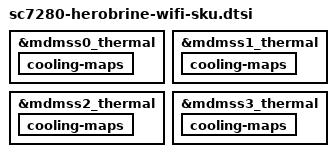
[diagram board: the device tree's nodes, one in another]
// SPDX-License-Identifier: BSD-3-Clause
/*
 * Google Herobrine dts fragment for WIFI SKUs
 *
 * Copyright (c) 2022 Qualcomm Innovation Center, Inc. All rights reserved.
 */

/* WIFI SKUs save 256M by not having modem/mba/rmtfs memory regions defined. */

&mdmss0_thermal {
	cooling-maps {
		/delete-node/ map0;
		/delete-node/ map1;
	};
};

&mdmss1_thermal {
	cooling-maps {
		/delete-node/ map0;
		/delete-node/ map1;
	};
};

&mdmss2_thermal {
	cooling-maps {
		/delete-node/ map0;
		/delete-node/ map1;
	};
};

&mdmss3_thermal {
	cooling-maps {
		/delete-node/ map0;
		/delete-node/ map1;
	};
};

/delete-node/ &mpss_mem;
/delete-node/ &remoteproc_mpss;
/delete-node/ &rmtfs_mem;
